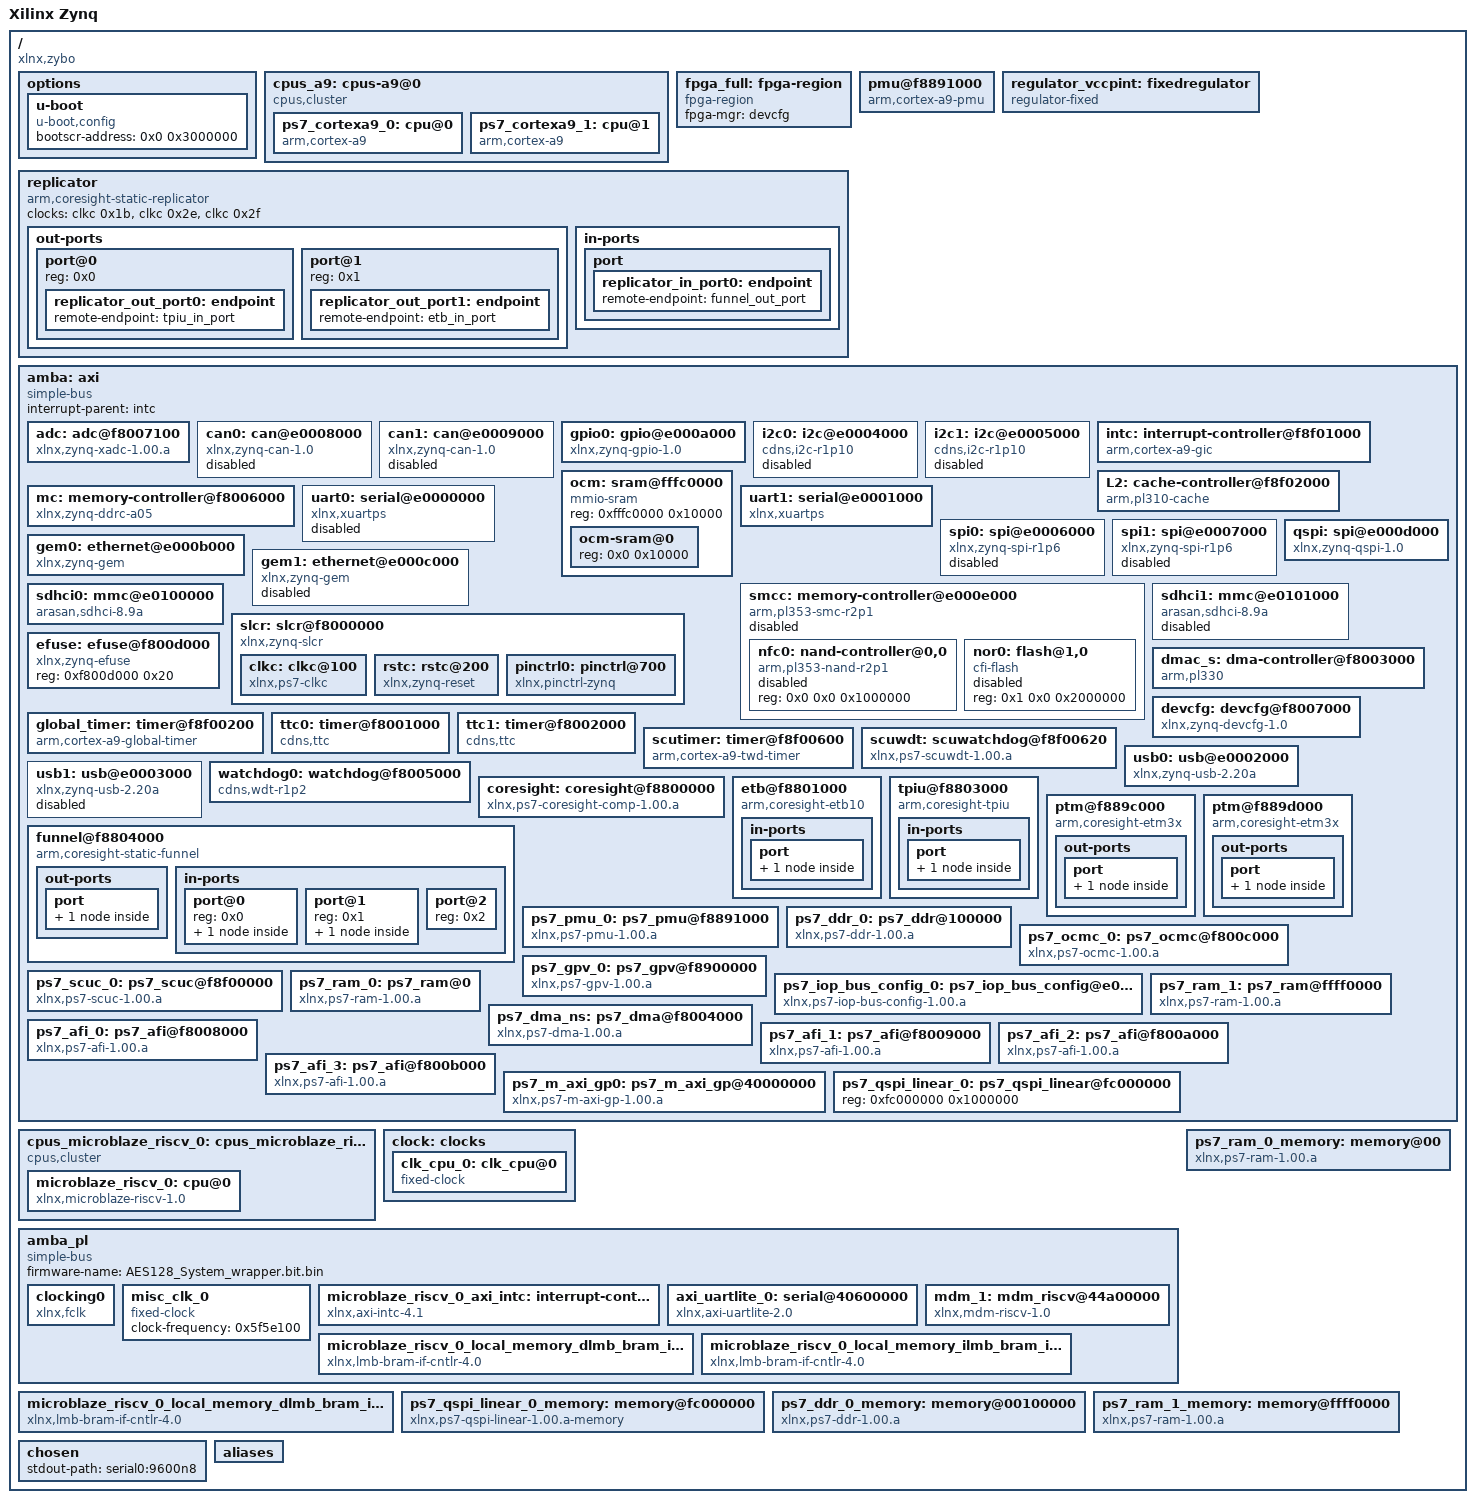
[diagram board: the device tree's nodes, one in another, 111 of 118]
/dts-v1/;
/ {
        #address-cells = <0x1>;
        #size-cells = <0x1>;
        compatible = "xlnx,zybo";
        model = "Xilinx Zynq";
        board = "zybo";
        device_id = "7z010";
        slrcount = <0x1>;
        family = "Zynq";
        speed_grade = "1";

        options {

                u-boot {
                        compatible = "u-boot,config";
                        bootscr-address = <0x0 0x3000000>;
                };
        };

        cpus_a9: cpus-a9@0 {
                phandle = <0x37>;
                #address-cells = <0x1>;
                #size-cells = <0x0>;
                compatible = "cpus,cluster";
                address-map = <0xf0000000 &amba 0xf0000000 0x10000000>,
                 <0x100000 &ps7_ddr_0_memory 0x100000 0x1ff00000>,
                 <0x0 &ps7_ram_0_memory 0x0 0x30000>,
                 <0xffff0000 &ps7_ram_1_memory 0xffff0000 0xfe00>,
                 <0x40600000 &axi_uartlite_0 0x40600000 0x10000>,
                 <0x41200000 &microblaze_riscv_0_axi_intc 0x41200000 0x10000>,
                 <0x44a00000 &mdm_1 0x44a00000 0x10000>,
                 <0xf8008000 &ps7_afi_0 0xf8008000 0x1000>,
                 <0xf8009000 &ps7_afi_1 0xf8009000 0x1000>,
                 <0xf800a000 &ps7_afi_2 0xf800a000 0x1000>,
                 <0xf800b000 &ps7_afi_3 0xf800b000 0x1000>,
                 <0xf8800000 &coresight 0xf8800000 0x100000>,
                 <0xf8006000 &mc 0xf8006000 0x1000>,
                 <0xf8007000 &devcfg 0xf8007000 0x100>,
                 <0xf8004000 &ps7_dma_ns 0xf8004000 0x1000>,
                 <0xf8003000 &dmac_s 0xf8003000 0x1000>,
                 <0xe000b000 &gem0 0xe000b000 0x1000>,
                 <0xf8f00200 &global_timer 0xf8f00200 0x100>,
                 <0xe000a000 &gpio0 0xe000a000 0x1000>,
                 <0xf8900000 &ps7_gpv_0 0xf8900000 0x100000>,
                 <0xf8f01000 &intc 0xf8f01000 0x1000>,
                 <0xe0200000 &ps7_iop_bus_config_0 0xe0200000 0x1000>,
                 <0xf8f02000 &L2 0xf8f02000 0x1000>,
                 <0xf800c000 &ps7_ocmc_0 0xf800c000 0x1000>,
                 <0xf8891000 &ps7_pmu_0 0xf8891000 0x1000>,
                 <0xe000d000 &qspi 0xe000d000 0x1000>,
                 <0xfc000000 &ps7_qspi_linear_0_memory 0xfc000000 0x1000000>,
                 <0xf8f00000 &ps7_scuc_0 0xf8f00000 0xfd>,
                 <0xf8f00600 &scutimer 0xf8f00600 0x20>,
                 <0xf8f00620 &scuwdt 0xf8f00620 0xe0>,
                 <0xe0100000 &sdhci0 0xe0100000 0x1000>,
                 <0xf8000000 &slcr 0xf8000000 0x1000>,
                 <0xf8001000 &ttc0 0xf8001000 0x1000>,
                 <0xe0001000 &uart1 0xe0001000 0x1000>,
                 <0xe0002000 &usb0 0xe0002000 0x1000>,
                 <0xf8007100 &adc 0xf8007100 0x21>;
                #ranges-address-cells = <0x1>;
                #ranges-size-cells = <0x1>;

                ps7_cortexa9_0: cpu@0 {
                        phandle = <0x2f>;
                        compatible = "arm,cortex-a9";
                        device_type = "cpu";
                        reg = <0x0>;
                        clocks = <&clkc 0x3>;
                        clock-latency = <0x3e8>;
                        cpu0-supply = <&regulator_vccpint>;
                        operating-points = <0xa2c2b 0xf4240 0x51616 0xf4240>;
                        xlnx,i-cache-size = <0x8000>;
                        xlnx,d-cache-line-size = <0x14>;
                        xlnx,i-cache-line-size = <0x14>;
                        xlnx,cpu-1x-clk-freq-hz = <0x6750918>;
                        xlnx,ip-name = "ps7_cortexa9";
                        xlnx,d-cache-size = <0x8000>;
                        xlnx,num-cores = <0x2>;
                        xlnx,cpu-clk-freq-hz = <0x26be3680>;
                        bus-handle = <0x1>;
                };

                ps7_cortexa9_1: cpu@1 {
                        phandle = <0x31>;
                        compatible = "arm,cortex-a9";
                        device_type = "cpu";
                        reg = <0x1>;
                        clocks = <&clkc 0x3>;
                        xlnx,i-cache-size = <0x8000>;
                        xlnx,d-cache-line-size = <0x14>;
                        xlnx,i-cache-line-size = <0x14>;
                        xlnx,cpu-1x-clk-freq-hz = <0x6750918>;
                        xlnx,ip-name = "ps7_cortexa9";
                        xlnx,d-cache-size = <0x8000>;
                        xlnx,cpu-clk-freq-hz = <0x26be3680>;
                        bus-handle = <0x1>;
                };
        };

        fpga_full: fpga-region {
                phandle = <0x38>;
                compatible = "fpga-region";
                fpga-mgr = <&devcfg>;
                #address-cells = <0x1>;
                #size-cells = <0x1>;
                ranges;
        };

        pmu@f8891000 {
                compatible = "arm,cortex-a9-pmu";
                interrupts = <0x0 0x5 0x4 0x0 0x6 0x4>;
                interrupt-parent = <&intc>;
                reg = <0xf8891000 0x1000 0xf8893000 0x1000>;
        };

        regulator_vccpint: fixedregulator {
                phandle = <0x26>;
                compatible = "regulator-fixed";
                regulator-name = "VCCPINT";
                regulator-min-microvolt = <0xf4240>;
                regulator-max-microvolt = <0xf4240>;
                regulator-boot-on;
                regulator-always-on;
        };

        replicator {
                compatible = "arm,coresight-static-replicator";
                clocks = <&clkc 0x1b>,
                 <&clkc 0x2e>,
                 <&clkc 0x2f>;
                clock-names = "apb_pclk", "dbg_trc", "dbg_apb";

                out-ports {
                        #address-cells = <0x1>;
                        #size-cells = <0x0>;

                        port@0 {
                                reg = <0x0>;

                                replicator_out_port0: endpoint {
                                        phandle = <0x2b>;
                                        remote-endpoint = <&tpiu_in_port>;
                                };
                        };

                        port@1 {
                                reg = <0x1>;

                                replicator_out_port1: endpoint {
                                        phandle = <0x2a>;
                                        remote-endpoint = <&etb_in_port>;
                                };
                        };
                };

                in-ports {

                        port {

                                replicator_in_port0: endpoint {
                                        phandle = <0x2c>;
                                        remote-endpoint = <&funnel_out_port>;
                                };
                        };
                };
        };

        amba: axi {
                phandle = <0x1>;
                bootph-all;
                compatible = "simple-bus";
                #address-cells = <0x1>;
                #size-cells = <0x1>;
                interrupt-parent = <&intc>;
                ranges;

                adc: adc@f8007100 {
                        phandle = <0x24>;
                        compatible = "xlnx,zynq-xadc-1.00.a";
                        reg = <0xf8007100 0x20>;
                        interrupts = <0x0 0x7 0x4>;
                        interrupt-parent = <&intc>;
                        clocks = <&clkc 0xc>;
                        status = "okay";
                        xlnx,ip-name = "ps7_xadc";
                        xlnx,name = "ps7_xadc_0";
                };

                can0: can@e0008000 {
                        phandle = <0x39>;
                        compatible = "xlnx,zynq-can-1.0";
                        status = "disabled";
                        clocks = <&clkc 0x13>,
                         <&clkc 0x24>;
                        clock-names = "can_clk", "pclk";
                        reg = <0xe0008000 0x1000>;
                        interrupts = <0x0 0x1c 0x4>;
                        interrupt-parent = <&intc>;
                        tx-fifo-depth = <0x40>;
                        rx-fifo-depth = <0x40>;
                };

                can1: can@e0009000 {
                        phandle = <0x3a>;
                        compatible = "xlnx,zynq-can-1.0";
                        status = "disabled";
                        clocks = <&clkc 0x14>,
                         <&clkc 0x25>;
                        clock-names = "can_clk", "pclk";
                        reg = <0xe0009000 0x1000>;
                        interrupts = <0x0 0x33 0x4>;
                        interrupt-parent = <&intc>;
                        tx-fifo-depth = <0x40>;
                        rx-fifo-depth = <0x40>;
                };

                gpio0: gpio@e000a000 {
                        phandle = <0x13>;
                        compatible = "xlnx,zynq-gpio-1.0";
                        #gpio-cells = <0x2>;
                        clocks = <&clkc 0x2a>;
                        gpio-controller;
                        interrupt-controller;
                        #interrupt-cells = <0x2>;
                        interrupt-parent = <&intc>;
                        interrupts = <0x0 0x14 0x4>;
                        reg = <0xe000a000 0x1000>;
                        xlnx,mio-gpio-mask = <0x5600>;
                        status = "okay";
                        gpio-mask-high = <0x0>;
                        xlnx,emio-gpio-width = <0x40>;
                        xlnx,ip-name = "ps7_gpio";
                        gpio-mask-low = <0x5600>;
                        emio-gpio-width = <0x40>;
                        xlnx,name = "ps7_gpio_0";
                };

                i2c0: i2c@e0004000 {
                        phandle = <0x3b>;
                        compatible = "cdns,i2c-r1p10";
                        status = "disabled";
                        clocks = <&clkc 0x26>;
                        interrupt-parent = <&intc>;
                        interrupts = <0x0 0x19 0x4>;
                        clock-frequency = <0x61a80>;
                        reg = <0xe0004000 0x1000>;
                        #address-cells = <0x1>;
                        #size-cells = <0x0>;
                };

                i2c1: i2c@e0005000 {
                        phandle = <0x3c>;
                        compatible = "cdns,i2c-r1p10";
                        status = "disabled";
                        clocks = <&clkc 0x27>;
                        interrupt-parent = <&intc>;
                        interrupts = <0x0 0x30 0x4>;
                        clock-frequency = <0x61a80>;
                        reg = <0xe0005000 0x1000>;
                        #address-cells = <0x1>;
                        #size-cells = <0x0>;
                };

                intc: interrupt-controller@f8f01000 {
                        phandle = <0x15>;
                        compatible = "arm,cortex-a9-gic";
                        #interrupt-cells = <0x3>;
                        interrupt-controller;
                        reg = <0xf8f01000 0x1000 0xf8f00100 0x100>;
                        status = "okay";
                        xlnx,irq-f2p-mode = "DIRECT";
                        xlnx,ip-name = "ps7_intc_dist";
                        xlnx,name = "ps7_intc_dist_0";
                };

                L2: cache-controller@f8f02000 {
                        phandle = <0x17>;
                        compatible = "arm,pl310-cache";
                        reg = <0xf8f02000 0x1000>;
                        interrupts = <0x0 0x2 0x4>;
                        arm,data-latency = <0x3 0x2 0x2>;
                        arm,tag-latency = <0x2 0x2 0x2>;
                        cache-unified;
                        cache-level = <0x2>;
                        status = "okay";
                        xlnx,ip-name = "ps7_pl310";
                        xlnx,name = "ps7_pl310_0";
                };

                mc: memory-controller@f8006000 {
                        phandle = <0xd>;
                        compatible = "xlnx,zynq-ddrc-a05";
                        reg = <0xf8006000 0x1000>;
                        status = "okay";
                        xlnx,ddr-clk-freq-hz = <0x1f4add40>;
                        xlnx,ip-name = "ps7_ddrc";
                        xlnx,has-ecc = <0x0>;
                        xlnx,name = "ps7_ddrc_0";
                };

                ocm: sram@fffc0000 {
                        phandle = <0x3d>;
                        compatible = "mmio-sram";
                        reg = <0xfffc0000 0x10000>;
                        #address-cells = <0x1>;
                        #size-cells = <0x1>;
                        ranges = <0x0 0xfffc0000 0x10000>;

                        ocm-sram@0 {
                                reg = <0x0 0x10000>;
                        };
                };

                uart0: serial@e0000000 {
                        phandle = <0x3e>;
                        compatible = "xlnx,xuartps", "cdns,uart-r1p8";
                        status = "disabled";
                        clocks = <&clkc 0x17>,
                         <&clkc 0x28>;
                        clock-names = "uart_clk", "pclk";
                        reg = <0xe0000000 0x1000>;
                        interrupts = <0x0 0x1b 0x4>;
                        interrupt-parent = <&intc>;
                };

                uart1: serial@e0001000 {
                        phandle = <0x22>;
                        compatible = "xlnx,xuartps", "cdns,uart-r1p8";
                        status = "okay";
                        clocks = <&clkc 0x18>,
                         <&clkc 0x29>;
                        clock-names = "uart_clk", "pclk";
                        reg = <0xe0001000 0x1000>;
                        interrupts = <0x0 0x32 0x4>;
                        interrupt-parent = <&intc>;
                        xlnx,clock-freq = <0x5f5e100>;
                        xlnx,has-modem = <0x0>;
                        xlnx,ip-name = "ps7_uart";
                        cts-override;
                        port-number = <0x0>;
                        xlnx,uart-clk-freq-hz = <0x5f5e100>;
                        xlnx,name = "ps7_uart_1";
                };

                spi0: spi@e0006000 {
                        phandle = <0x3f>;
                        compatible = "xlnx,zynq-spi-r1p6";
                        reg = <0xe0006000 0x1000>;
                        status = "disabled";
                        interrupt-parent = <&intc>;
                        interrupts = <0x0 0x1a 0x4>;
                        clocks = <&clkc 0x19>,
                         <&clkc 0x22>;
                        clock-names = "ref_clk", "pclk";
                        #address-cells = <0x1>;
                        #size-cells = <0x0>;
                };

                spi1: spi@e0007000 {
                        phandle = <0x40>;
                        compatible = "xlnx,zynq-spi-r1p6";
                        reg = <0xe0007000 0x1000>;
                        status = "disabled";
                        interrupt-parent = <&intc>;
                        interrupts = <0x0 0x31 0x4>;
                        clocks = <&clkc 0x1a>,
                         <&clkc 0x23>;
                        clock-names = "ref_clk", "pclk";
                        #address-cells = <0x1>;
                        #size-cells = <0x0>;
                };

                qspi: spi@e000d000 {
                        phandle = <0x1a>;
                        compatible = "xlnx,zynq-qspi-1.0";
                        reg = <0xe000d000 0x1000>;
                        interrupt-parent = <&intc>;
                        interrupts = <0x0 0x13 0x4>;
                        clocks = <&clkc 0xa>,
                         <&clkc 0x2b>;
                        clock-names = "ref_clk", "pclk";
                        status = "okay";
                        #address-cells = <0x1>;
                        #size-cells = <0x0>;
                        xlnx,qspi-fbclk = <0x0>;
                        num-cs = <0x1>;
                        xlnx,qspi-clk-freq-hz = <0xbebc200>;
                        xlnx,bus-width = <0x2>;
                        xlnx,ip-name = "ps7_qspi";
                        spi-rx-bus-width = <0x4>;
                        xlnx,connection-mode = <0x0>;
                        spi-tx-bus-width = <0x4>;
                        xlnx,clock-freq = <0xbebc200>;
                        xlnx,fb-clk = <0x1>;
                        xlnx,qspi-mode = <0x0>;
                        xlnx,name = "ps7_qspi_0";
                        xlnx,qspi-bus-width = <0x2>;
                        is-dual = <0x0>;
                };

                gem0: ethernet@e000b000 {
                        phandle = <0x11>;
                        compatible = "xlnx,zynq-gem", "cdns,gem";
                        reg = <0xe000b000 0x1000>;
                        status = "okay";
                        interrupts = <0x0 0x16 0x4>;
                        interrupt-parent = <&intc>;
                        clocks = <&clkc 0x1e>,
                         <&clkc 0x1e>,
                         <&clkc 0xd>;
                        clock-names = "pclk", "hclk", "tx_clk";
                        #address-cells = <0x1>;
                        #size-cells = <0x0>;
                        xlnx,has-mdio = <0x1>;
                        phy-mode = "rgmii-id";
                        xlnx,enet-slcr-1000mbps-div0 = <0x8>;
                        xlnx,enet-slcr-10mbps-div0 = <0x8>;
                        xlnx,enet-slcr-1000mbps-div1 = <0x1>;
                        xlnx,enet-slcr-10mbps-div1 = <0x32>;
                        xlnx,ip-name = "ps7_ethernet";
                        xlnx,eth-mode = <0x1>;
                        xlnx,enet-clk-freq-hz = <0x7735940>;
                        xlnx,enet-slcr-100mbps-div0 = <0x8>;
                        xlnx,enet-slcr-100mbps-div1 = <0x5>;
                        xlnx,name = "ps7_ethernet_0";
                };

                gem1: ethernet@e000c000 {
                        phandle = <0x41>;
                        compatible = "xlnx,zynq-gem", "cdns,gem";
                        reg = <0xe000c000 0x1000>;
                        status = "disabled";
                        interrupts = <0x0 0x2d 0x4>;
                        interrupt-parent = <&intc>;
                        clocks = <&clkc 0x1f>,
                         <&clkc 0x1f>,
                         <&clkc 0xe>;
                        clock-names = "pclk", "hclk", "tx_clk";
                        #address-cells = <0x1>;
                        #size-cells = <0x0>;
                };

                smcc: memory-controller@e000e000 {
                        phandle = <0x42>;
                        compatible = "arm,pl353-smc-r2p1", "arm,primecell";
                        reg = <0xe000e000 0x1000>;
                        status = "disabled";
                        clock-names = "memclk", "apb_pclk";
                        clocks = <&clkc 0xb>,
                         <&clkc 0x2c>;
                        ranges = <0x0 0x0 0xe1000000 0x1000000 0x1 0x0 0xe2000000 0x2000000 0x2 0x0 0xe4000000 0x2000000>;
                        #address-cells = <0x2>;
                        #size-cells = <0x1>;
                        interrupt-parent = <&intc>;
                        interrupts = <0x0 0x12 0x4>;

                        nfc0: nand-controller@0,0 {
                                phandle = <0x43>;
                                compatible = "arm,pl353-nand-r2p1";
                                reg = <0x0 0x0 0x1000000>;
                                status = "disabled";
                        };

                        nor0: flash@1,0 {
                                phandle = <0x44>;
                                status = "disabled";
                                compatible = "cfi-flash";
                                reg = <0x1 0x0 0x2000000>;
                        };
                };

                sdhci0: mmc@e0100000 {
                        phandle = <0x1f>;
                        compatible = "arasan,sdhci-8.9a";
                        status = "okay";
                        clock-names = "clk_xin", "clk_ahb";
                        clocks = <&clkc 0x15>,
                         <&clkc 0x20>;
                        interrupt-parent = <&intc>;
                        interrupts = <0x0 0x18 0x4>;
                        reg = <0xe0100000 0x1000>;
                        xlnx,has-power = <0x0>;
                        xlnx,ip-name = "ps7_sdio";
                        xlnx,sdio-clk-freq-hz = <0x2faf080>;
                        xlnx,has-wp = <0x1>;
                        xlnx,has-cd = <0x1>;
                        xlnx,name = "ps7_sd_0";
                };

                sdhci1: mmc@e0101000 {
                        phandle = <0x45>;
                        compatible = "arasan,sdhci-8.9a";
                        status = "disabled";
                        clock-names = "clk_xin", "clk_ahb";
                        clocks = <&clkc 0x16>,
                         <&clkc 0x21>;
                        interrupt-parent = <&intc>;
                        interrupts = <0x0 0x2f 0x4>;
                        reg = <0xe0101000 0x1000>;
                };

                slcr: slcr@f8000000 {
                        phandle = <0x20>;
                        bootph-all;
                        #address-cells = <0x1>;
                        #size-cells = <0x1>;
                        compatible = "xlnx,zynq-slcr", "syscon", "simple-mfd";
                        reg = <0xf8000000 0x1000>;
                        ranges;
                        status = "okay";
                        xlnx,ip-name = "ps7_slcr";
                        xlnx,name = "ps7_slcr_0";

                        clkc: clkc@100 {
                                phandle = <0x25>;
                                bootph-all;
                                #clock-cells = <0x1>;
                                compatible = "xlnx,ps7-clkc";
                                fclk-enable = <0x1>;
                                clock-output-names = "armpll", "ddrpll", "iopll", "cpu_6or4x", "cpu_3or2x", "cpu_2x", "cpu_1x", "ddr2x", "ddr3x", "dci", "lqspi", "smc", "pcap", "gem0", "gem1", "fclk0", "fclk1", "fclk2", "fclk3", "can0", "can1", "sdio0", "sdio1", "uart0", "uart1", "spi0", "spi1", "dma", "usb0_aper", "usb1_aper", "gem0_aper", "gem1_aper", "sdio0_aper", "sdio1_aper", "spi0_aper", "spi1_aper", "can0_aper", "can1_aper", "i2c0_aper", "i2c1_aper", "uart0_aper", "uart1_aper", "gpio_aper", "lqspi_aper", "smc_aper", "swdt", "dbg_trc", "dbg_apb";
                                reg = <0x100 0x100>;
                                ps-clk-frequency = <0x2faf080>;
                        };

                        rstc: rstc@200 {
                                phandle = <0x46>;
                                compatible = "xlnx,zynq-reset";
                                reg = <0x200 0x48>;
                                #reset-cells = <0x1>;
                                syscon = <&slcr>;
                        };

                        pinctrl0: pinctrl@700 {
                                phandle = <0x47>;
                                compatible = "xlnx,pinctrl-zynq";
                                reg = <0x700 0x200>;
                                syscon = <&slcr>;
                        };
                };

                dmac_s: dma-controller@f8003000 {
                        phandle = <0x10>;
                        compatible = "arm,pl330", "arm,primecell";
                        reg = <0xf8003000 0x1000>;
                        interrupt-parent = <&intc>;
                        interrupts = <0x0 0xd 0x4 0x0 0xe 0x4 0x0 0xf 0x4 0x0 0x10 0x4 0x0 0x11 0x4 0x0 0x28 0x4 0x0 0x29 0x4 0x0 0x2a 0x4 0x0 0x2b 0x4>;
                        #dma-cells = <0x1>;
                        clocks = <&clkc 0x1b>;
                        clock-names = "apb_pclk";
                        status = "okay";
                        xlnx,ip-name = "ps7_dma";
                        xlnx,is-secure;
                        xlnx,name = "ps7_dma_s";
                };

                devcfg: devcfg@f8007000 {
                        phandle = <0xe>;
                        compatible = "xlnx,zynq-devcfg-1.0";
                        reg = <0xf8007000 0x100>;
                        interrupt-parent = <&intc>;
                        interrupts = <0x0 0x8 0x4>;
                        clocks = <&clkc 0xc>,
                         <&clkc 0xf>,
                         <&clkc 0x10>,
                         <&clkc 0x11>,
                         <&clkc 0x12>;
                        clock-names = "ref_clk", "fclk0", "fclk1", "fclk2", "fclk3";
                        syscon = <&slcr>;
                        status = "okay";
                        xlnx,ip-name = "ps7_dev_cfg";
                        xlnx,name = "ps7_dev_cfg_0";
                };

                efuse: efuse@f800d000 {
                        phandle = <0x48>;
                        compatible = "xlnx,zynq-efuse";
                        reg = <0xf800d000 0x20>;
                };

                global_timer: timer@f8f00200 {
                        phandle = <0x12>;
                        compatible = "arm,cortex-a9-global-timer";
                        reg = <0xf8f00200 0x20>;
                        interrupts = <0x1 0xb 0x301>;
                        interrupt-parent = <&intc>;
                        clocks = <&clkc 0x4>;
                        status = "okay";
                        xlnx,ip-name = "ps7_globaltimer";
                        xlnx,name = "ps7_globaltimer_0";
                };

                ttc0: timer@f8001000 {
                        phandle = <0x21>;
                        interrupt-parent = <&intc>;
                        interrupts = <0x0 0xa 0x4 0x0 0xb 0x4 0x0 0xc 0x4>;
                        compatible = "cdns,ttc";
                        clocks = <&clkc 0x6>;
                        reg = <0xf8001000 0x1000>;
                        xlnx,ttc-clk2-freq-hz = <0x6750918>;
                        xlnx,ttc-clk1-clksrc = <0x0>;
                        status = "okay";
                        xlnx,clock-freq = <0x6750918>;
                        xlnx,ttc-clk2-clksrc = <0x0>;
                        xlnx,ip-name = "ps7_ttc";
                        xlnx,ttc-clk0-freq-hz = <0x6750918>;
                        xlnx,ttc-clk1-freq-hz = <0x6750918>;
                        xlnx,ttc-clk0-clksrc = <0x0>;
                        xlnx,name = "ps7_ttc_0";
                };

                ttc1: timer@f8002000 {
                        phandle = <0x49>;
                        interrupt-parent = <&intc>;
                        interrupts = <0x0 0x25 0x4 0x0 0x26 0x4 0x0 0x27 0x4>;
                        compatible = "cdns,ttc";
                        clocks = <&clkc 0x6>;
                        reg = <0xf8002000 0x1000>;
                };

                scutimer: timer@f8f00600 {
                        phandle = <0x1d>;
                        bootph-all;
                        interrupt-parent = <&intc>;
                        interrupts = <0x1 0xd 0x301>;
                        compatible = "arm,cortex-a9-twd-timer";
                        reg = <0xf8f00600 0x20>;
                        clocks = <&clkc 0x4>;
                        status = "okay";
                        xlnx,ip-name = "ps7_scutimer";
                        xlnx,name = "ps7_scutimer_0";
                };

                scuwdt: scuwatchdog@f8f00620 {
                        phandle = <0x1e>;
                        interrupt-parent = <&intc>;
                        interrupts = <0x1 0xe 0x4>;
                        compatible = "xlnx,ps7-scuwdt-1.00.a";
                        reg = <0xf8f00620 0xe0>;
                        status = "okay";
                        xlnx,ip-name = "ps7_scuwdt";
                        xlnx,name = "ps7_scuwdt_0";
                };

                usb0: usb@e0002000 {
                        phandle = <0x23>;
                        compatible = "xlnx,zynq-usb-2.20a", "chipidea,usb2";
                        status = "okay";
                        clocks = <&clkc 0x1c>;
                        interrupt-parent = <&intc>;
                        interrupts = <0x0 0x15 0x4>;
                        reg = <0xe0002000 0x1000>;
                        phy_type = "ulpi";
                        xlnx,usb-reset = "MIO , 46";
                        xlnx,ip-name = "ps7_usb";
                        xlnx,enable-superspeed = <0x0>;
                        usb-reset = <0x13 0x2e 0x0>;
                        xlnx,name = "ps7_usb_0";
                };

                usb1: usb@e0003000 {
                        phandle = <0x4a>;
                        compatible = "xlnx,zynq-usb-2.20a", "chipidea,usb2";
                        status = "disabled";
                        clocks = <&clkc 0x1d>;
                        interrupt-parent = <&intc>;
                        interrupts = <0x0 0x2c 0x4>;
                        reg = <0xe0003000 0x1000>;
                        phy_type = "ulpi";
                };

                watchdog0: watchdog@f8005000 {
                        phandle = <0x4b>;
                        clocks = <&clkc 0x2d>;
                        compatible = "cdns,wdt-r1p2";
                        interrupt-parent = <&intc>;
                        interrupts = <0x0 0x9 0x1>;
                        reg = <0xf8005000 0x1000>;
                        timeout-sec = <0xa>;
                };

                coresight: coresight@f8800000 {
                        phandle = <0xc>;
                        compatible = "xlnx,ps7-coresight-comp-1.00.a";
                        status = "okay";
                        reg = <0xf8800000 0x100000>;
                        xlnx,ip-name = "ps7_coresight_comp";
                        xlnx,name = "ps7_coresight_comp_0";
                };

                etb@f8801000 {
                        compatible = "arm,coresight-etb10", "arm,primecell";
                        reg = <0xf8801000 0x1000>;
                        clocks = <&clkc 0x1b>,
                         <&clkc 0x2e>,
                         <&clkc 0x2f>;
                        clock-names = "apb_pclk", "dbg_trc", "dbg_apb";

                        in-ports {

                                port {

                                        etb_in_port: endpoint {
                                                phandle = <0x28>;
                                                remote-endpoint = <&replicator_out_port1>;
                                        };
                                };
                        };
                };

                tpiu@f8803000 {
                        compatible = "arm,coresight-tpiu", "arm,primecell";
                        reg = <0xf8803000 0x1000>;
                        clocks = <&clkc 0x1b>,
                         <&clkc 0x2e>,
                         <&clkc 0x2f>;
                        clock-names = "apb_pclk", "dbg_trc", "dbg_apb";

                        in-ports {

                                port {

                                        tpiu_in_port: endpoint {
                                                phandle = <0x27>;
                                                remote-endpoint = <&replicator_out_port0>;
                                        };
                                };
                        };
                };

                funnel@f8804000 {
                        compatible = "arm,coresight-static-funnel", "arm,primecell";
                        reg = <0xf8804000 0x1000>;
                        clocks = <&clkc 0x1b>,
                         <&clkc 0x2e>,
                         <&clkc 0x2f>;
                        clock-names = "apb_pclk", "dbg_trc", "dbg_apb";

                        out-ports {

                                port {

                                        funnel_out_port: endpoint {
                                                phandle = <0x29>;
                                                remote-endpoint = <&replicator_in_port0>;
                                        };
                                };
                        };

                        in-ports {
                                #address-cells = <0x1>;
                                #size-cells = <0x0>;

                                port@0 {
                                        reg = <0x0>;

                                        funnel0_in_port0: endpoint {
                                                phandle = <0x30>;
                                                remote-endpoint = <&ptm0_out_port>;
                                        };
                                };

                                port@1 {
                                        reg = <0x1>;

                                        funnel0_in_port1: endpoint {
                                                phandle = <0x32>;
                                                remote-endpoint = <&ptm1_out_port>;
                                        };
                                };

                                port@2 {
                                        reg = <0x2>;
                                };
                        };
                };

                ptm@f889c000 {
                        compatible = "arm,coresight-etm3x", "arm,primecell";
                        reg = <0xf889c000 0x1000>;
                        clocks = <&clkc 0x1b>,
                         <&clkc 0x2e>,
                         <&clkc 0x2f>;
                        clock-names = "apb_pclk", "dbg_trc", "dbg_apb";
                        cpu = <&ps7_cortexa9_0>;

                        out-ports {

                                port {

                                        ptm0_out_port: endpoint {
                                                phandle = <0x2d>;
                                                remote-endpoint = <&funnel0_in_port0>;
                                        };
                                };
                        };
                };

                ptm@f889d000 {
                        compatible = "arm,coresight-etm3x", "arm,primecell";
                        reg = <0xf889d000 0x1000>;
                        clocks = <&clkc 0x1b>,
                         <&clkc 0x2e>,
                         <&clkc 0x2f>;
                        clock-names = "apb_pclk", "dbg_trc", "dbg_apb";
                        cpu = <&ps7_cortexa9_1>;

                        out-ports {

                                port {

                                        ptm1_out_port: endpoint {
                                                phandle = <0x2e>;
                                                remote-endpoint = <&funnel0_in_port1>;
                                        };
                                };
                        };
                };

                ps7_pmu_0: ps7_pmu@f8891000 {
                        phandle = <0x19>;
                        compatible = "xlnx,ps7-pmu-1.00.a";
                        status = "okay";
                        xlnx,ip-name = "ps7_pmu";
                        reg = <0xf8891000 0x1000 0xf8893000 0x1000>;
                        xlnx,name = "ps7_pmu_0";
                };

                ps7_ddr_0: ps7_ddr@100000 {
                        phandle = <0x4c>;
                        compatible = "xlnx,ps7-ddr-1.00.a";
                        status = "okay";
                        xlnx,ip-name = "ps7_ddr";
                        reg = <0x100000 0x1ff00000>;
                        xlnx,name = "ps7_ddr_0";
                };

                ps7_ocmc_0: ps7_ocmc@f800c000 {
                        phandle = <0x18>;
                        compatible = "xlnx,ps7-ocmc-1.00.a";
                        status = "okay";
                        xlnx,ip-name = "ps7_ocmc";
                        reg = <0xf800c000 0x1000>;
                        xlnx,name = "ps7_ocmc_0";
                };

                ps7_gpv_0: ps7_gpv@f8900000 {
                        phandle = <0x14>;
                        compatible = "xlnx,ps7-gpv-1.00.a";
                        status = "okay";
                        xlnx,ip-name = "ps7_gpv";
                        reg = <0xf8900000 0x100000>;
                        xlnx,name = "ps7_gpv_0";
                };

                ps7_scuc_0: ps7_scuc@f8f00000 {
                        phandle = <0x1c>;
                        compatible = "xlnx,ps7-scuc-1.00.a";
                        status = "okay";
                        xlnx,ip-name = "ps7_scuc";
                        reg = <0xf8f00000 0xfd>;
                        xlnx,name = "ps7_scuc_0";
                };

                ps7_iop_bus_config_0: ps7_iop_bus_config@e0200000 {
                        phandle = <0x16>;
                        compatible = "xlnx,ps7-iop-bus-config-1.00.a";
                        status = "okay";
                        xlnx,ip-name = "ps7_iop_bus_config";
                        reg = <0xe0200000 0x1000>;
                        xlnx,name = "ps7_iop_bus_config_0";
                };

                ps7_ram_0: ps7_ram@0 {
                        phandle = <0x4d>;
                        compatible = "xlnx,ps7-ram-1.00.a";
                        status = "okay";
                        xlnx,ip-name = "ps7_ram";
                        reg = <0x0 0x30000>;
                        xlnx,name = "ps7_ram_0";
                };

                ps7_ram_1: ps7_ram@ffff0000 {
                        phandle = <0x4e>;
                        compatible = "xlnx,ps7-ram-1.00.a";
                        status = "okay";
                        xlnx,ip-name = "ps7_ram";
                        reg = <0xffff0000 0xfe00>;
                        xlnx,name = "ps7_ram_1";
                };

                ps7_dma_ns: ps7_dma@f8004000 {
                        phandle = <0xf>;
                        compatible = "xlnx,ps7-dma-1.00.a";
                        status = "okay";
                        xlnx,ip-name = "ps7_dma";
                        xlnx,is-secure;
                        reg = <0xf8004000 0x1000>;
                        xlnx,name = "ps7_dma_ns";
                };

                ps7_afi_0: ps7_afi@f8008000 {
                        phandle = <0x8>;
                        compatible = "xlnx,ps7-afi-1.00.a";
                        status = "okay";
                        xlnx,ip-name = "ps7_afi";
                        reg = <0xf8008000 0x1000>;
                        xlnx,name = "ps7_afi_0";
                };

                ps7_afi_1: ps7_afi@f8009000 {
                        phandle = <0x9>;
                        compatible = "xlnx,ps7-afi-1.00.a";
                        status = "okay";
                        xlnx,ip-name = "ps7_afi";
                        reg = <0xf8009000 0x1000>;
                        xlnx,name = "ps7_afi_1";
                };

                ps7_afi_2: ps7_afi@f800a000 {
                        phandle = <0xa>;
                        compatible = "xlnx,ps7-afi-1.00.a";
                        status = "okay";
                        xlnx,ip-name = "ps7_afi";
                        reg = <0xf800a000 0x1000>;
                        xlnx,name = "ps7_afi_2";
                };

                ps7_afi_3: ps7_afi@f800b000 {
                        phandle = <0xb>;
                        compatible = "xlnx,ps7-afi-1.00.a";
                        status = "okay";
                        xlnx,ip-name = "ps7_afi";
                        reg = <0xf800b000 0x1000>;
                        xlnx,name = "ps7_afi_3";
                };

                ps7_m_axi_gp0: ps7_m_axi_gp@40000000 {
                        phandle = <0x4f>;
                        compatible = "xlnx,ps7-m-axi-gp-1.00.a";
                        status = "okay";
                        xlnx,ip-name = "ps7_m_axi_gp";
                        xlnx,is-hierarchy;
                        reg = <0x40000000 0x40000000>;
                        xlnx,name = "ps7_m_axi_gp0";
                };

                ps7_qspi_linear_0: ps7_qspi_linear@fc000000 {
                        phandle = <0x50>;
                        reg = <0xfc000000 0x1000000>;
                };
        };

        cpus_microblaze_riscv_0: cpus_microblaze_riscv@0 {
                phandle = <0x51>;
                #cpu-mask-cells = <0x1>;
                compatible = "cpus,cluster";
                #address-cells = <0x1>;
                #size-cells = <0x0>;
                address-map = <0x0 &microblaze_riscv_0_local_memory_dlmb_bram_if_cntlr_memory 0x0 0x8000>,
                 <0x0 &microblaze_riscv_0_local_memory_dlmb_bram_if_cntlr 0x0 0x8000>,
                 <0x40600000 &axi_uartlite_0 0x40600000 0x10000>,
                 <0x41200000 &microblaze_riscv_0_axi_intc 0x41200000 0x10000>,
                 <0x44a00000 &mdm_1 0x44a00000 0x10000>;
                #ranges-address-cells = <0x1>;
                #ranges-size-cells = <0x1>;

                microblaze_riscv_0: cpu@0 {
                        phandle = <0x52>;
                        xlnx,d-axi = <0x1>;
                        xlnx,pmp-entries = <0x0>;
                        xlnx,temporal-depth = <0x0>;
                        xlnx,dcache-force-tag-lutram = <0x0>;
                        reg = <0x0>;
                        xlnx,interrupt-is-edge = <0x0>;
                        xlnx,use-mmu = <0x0>;
                        xlnx,dc-axi-mon = <0x0>;
                        xlnx,debug-trace-async-reset = <0x0>;
                        xlnx,part = "xc7z010clg400-1";
                        xlnx,use-config-reset = <0x0>;
                        xlnx,family = "zynq";
                        xlnx,use-sleep = <0x0>;
                        xlnx,d-lmb = <0x1>;
                        xlnx,enable-discrete-ports = <0x0>;
                        xlnx,debug-interface = <0x0>;
                        xlnx,use-ext-brk = <0x0>;
                        xlnx,debug-enabled = <0x1>;
                        xlnx,daddr-size = <0x20>;
                        xlnx,use-extended-fsl-instr = <0x0>;
                        xlnx,branch-target-cache-size = <0x0>;
                        bus-handle = <0x35>;
                        xlnx,pmp-addr0 = <0x0>;
                        xlnx,pmp-addr1 = <0x0>;
                        xlnx,pmp-addr2 = <0x0>;
                        xlnx,pmp-addr3 = <0x0>;
                        xlnx,pmp-addr4 = <0x0>;
                        xlnx,edk-special = "microblaze_riscv";
                        xlnx,use-dcache = <0x0>;
                        xlnx,pmp-addr5 = <0x0>;
                        xlnx,use-muldiv = <0x0>;
                        xlnx,pmp-addr6 = <0x0>;
                        xlnx,use-axi-dp-ext-addr = <0x0>;
                        xlnx,pmp-addr7 = <0x0>;
                        xlnx,pmp-addr8 = <0x0>;
                        xlnx,pmp-addr9 = <0x0>;
                        xlnx,i-axi = <0x0>;
                        xlnx,icache-streams = <0x0>;
                        xlnx,i-lmb-has-prot = <0x0>;
                        xlnx,num-sync-ff-dbg-clk = <0x1>;
                        xlnx,icache-byte-size = <0x2000>;
                        xlnx,pmp-addr10 = <0x0>;
                        d-cache-size = <0x2000>;
                        xlnx,pmp-addr11 = <0x0>;
                        xlnx,pmp-addr12 = <0x0>;
                        xlnx,pmp-addr13 = <0x0>;
                        xlnx,pmp-addr14 = <0x0>;
                        xlnx,pmp-addr15 = <0x0>;
                        xlnx,avoid-primitives = <0x0>;
                        xlnx,pmp-addr16 = <0x0>;
                        xlnx,pmp-addr17 = <0x0>;
                        xlnx,pmp-addr18 = <0x0>;
                        xlnx,pdaddr-size = <0x20>;
                        xlnx,pmp-addr19 = <0x0>;
                        xlnx,pmp-addr20 = <0x0>;
                        xlnx,pmp-addr21 = <0x0>;
                        xlnx,i-lmb = <0x1>;
                        xlnx,pmp-addr22 = <0x0>;
                        xlnx,lmb-data-size = <0x20>;
                        xlnx,lockstep-select = <0x0>;
                        xlnx,pmp-addr23 = <0x0>;
                        timebase-frequency = <0x5f5e100>;
                        xlnx,pmp-addr24 = <0x0>;
                        xlnx,dcache-data-width = <0x0>;
                        xlnx,icache-force-tag-lutram = <0x0>;
                        xlnx,pmp-addr25 = <0x0>;
                        xlnx,pmp-addr26 = <0x0>;
                        xlnx,use-branch-target-cache = <0x0>;
                        xlnx,pmp-addr27 = <0x0>;
                        xlnx,number-of-pc-brk = <0x1>;
                        xlnx,pmp-addr28 = <0x0>;
                        xlnx,imprecise-exceptions = <0x0>;
                        xlnx,pmp-addr29 = <0x0>;
                        xlnx,pmp-addr30 = <0x0>;
                        xlnx,pmp-addr31 = <0x0>;
                        xlnx,pmp-addr32 = <0x0>;
                        model = "microblaze_riscv,1.0";
                        xlnx,pmp-addr33 = <0x0>;
                        xlnx,pmp-addr34 = <0x0>;
                        xlnx,pmp-addr35 = <0x0>;
                        xlnx,pmp-addr36 = <0x0>;
                        d-cache-highaddr = <0x3fffffff>;
                        xlnx,optimization = <0x0>;
                        xlnx,pmp-addr37 = <0x0>;
                        xlnx,pmp-addr38 = <0x0>;
                        xlnx,pmp-addr39 = <0x0>;
                        xlnx,pmp-addr40 = <0x0>;
                        xlnx,pmp-addr41 = <0x0>;
                        xlnx,d-lmb-mon = <0x0>;
                        xlnx,pmp-addr42 = <0x0>;
                        xlnx,pmp-addr43 = <0x0>;
                        xlnx,pmp-addr44 = <0x0>;
                        xlnx,pmp-addr45 = <0x0>;
                        xlnx,pmp-addr46 = <0x0>;
                        xlnx,pmp-addr47 = <0x0>;
                        xlnx,pmp-addr48 = <0x0>;
                        xlnx,fault-tolerant = <0x0>;
                        xlnx,pmp-addr49 = <0x0>;
                        xlnx,pmp-addr50 = <0x0>;
                        xlnx,pmp-addr51 = <0x0>;
                        xlnx,pmp-enhancements = <0x0>;
                        d-cache-line-size = <0x10>;
                        xlnx,mmu-privileged-instr = <0x0>;
                        xlnx,pmp-addr52 = <0x0>;
                        clock-frequency = <0x5f5e100>;
                        xlnx,pmp-addr53 = <0x0>;
                        xlnx,pmp-addr54 = <0x0>;
                        xlnx,pmp-addr55 = <0x0>;
                        xlnx,i-lmb-protocol = <0x0>;
                        xlnx,pmp-addr56 = <0x0>;
                        xlnx,pmp-addr57 = <0x0>;
                        xlnx,dp-axi-mon = <0x0>;
                        xlnx,pmp-addr58 = <0x0>;
                        xlnx,pmp-addr59 = <0x0>;
                        xlnx,pmp-addr60 = <0x0>;
                        xlnx,pmp-addr61 = <0x0>;
                        xlnx,pmp-addr62 = <0x0>;
                        xlnx,pmp-addr63 = <0x0>;
                        xlnx,debug-external-trace = <0x0>;
                        xlnx,addr-size = <0x20>;
                        xlnx,debug-num-progbuf = <0x2>;
                        xlnx,debug-event-counters = <0x0>;
                        xlnx,edk-iptype = "PROCESSOR";
                        xlnx,debug-latency-counters = <0x0>;
                        xlnx,interconnect = <0x2>;
                        xlnx,edge-is-positive = <0x1>;
                        xlnx,use-icache = <0x0>;
                        xlnx,async-wakeup = <0x3>;
                        xlnx,s-axi = <0x0>;
                        xlnx,use-ext-nm-brk = <0x0>;
                        xlnx,ic-axi-mon = <0x0>;
                        xlnx,archid = <0x1>;
                        xlnx,num-sync-ff-clk-irq = <0x1>;
                        xlnx,freq = <0x5f5e100>;
                        xlnx,lockstep-master = <0x0>;
                        xlnx,pmp-cfg0 = <0x0>;
                        xlnx,pmp-cfg1 = <0x0>;
                        xlnx,iaddr-size = <0x20>;
                        xlnx,interrupt-mon = <0x0>;
                        xlnx,pmp-cfg2 = <0x0>;
                        xlnx,number-of-wr-addr-brk = <0x0>;
                        xlnx,pmp-cfg3 = <0x0>;
                        xlnx,pmp-cfg4 = <0x0>;
                        xlnx,use-interrupt = <0x2>;
                        xlnx,pmp-cfg5 = <0x0>;
                        xlnx,async-interrupt = <0x1>;
                        xlnx,pc-width = <0xf>;
                        xlnx,pmp-cfg6 = <0x0>;
                        xlnx,icache-victims = <0x0>;
                        xlnx,pmp-cfg7 = <0x0>;
                        xlnx,pmp-cfg8 = <0x0>;
                        xlnx,pmp-cfg9 = <0x0>;
                        xlnx,use-bitman-a = <0x0>;
                        xlnx,use-bitman-b = <0x0>;
                        xlnx,use-bitman-c = <0x0>;
                        xlnx,i-lmb-mon = <0x0>;
                        xlnx,dcache-byte-size = <0x2000>;
                        xlnx,data-size = <0x20>;
                        compatible = "xlnx,microblaze-riscv-1.0", "xlnx,microblaze_riscv";
                        xlnx,pmp-debug-inhibit = <0x0>;
                        xlnx,use-sstc = <0x1>;
                        xlnx,fsl-exception = <0x0>;
                        xlnx,dcache-use-writeback = <0x0>;
                        device_type = "cpu";
                        xlnx,impid = <0x1>;
                        xlnx,use-bitman-s = <0x0>;
                        xlnx,base-vectors = <0x0>;
                        xlnx,icache-line-len = <0x4>;
                        xlnx,d-lmb-has-prot = <0x0>;
                        xlnx,use-barrel = <0x1>;
                        xlnx,misaligned-exceptions = <0x1>;
                        xlnx,piaddr-size = <0x20>;
                        xlnx,use-bitman = <0x0>;
                        xlnx,dcache-line-len = <0x4>;
                        xlnx,num-sync-ff-clk = <0x2>;
                        xlnx,memory-ip-list = "microblaze_riscv_0_local_memory_ilmb_bram_if_cntlr_memory", "microblaze_riscv_0_local_memory_dlmb_bram_if_cntlr_memory";
                        xlnx,number-of-rd-addr-brk = <0x0>;
                        xlnx,use-counters = <0x1>;
                        xlnx,lockstep-slave = <0x0>;
                        interrupt-handle = <0x6>;
                        xlnx,pmp-cfg10 = <0x0>;
                        xlnx,pmp-cfg11 = <0x0>;
                        xlnx,debug-profile-size = <0x0>;
                        xlnx,pmp-cfg12 = <0x0>;
                        xlnx,pmp-cfg13 = <0x0>;
                        xlnx,pmp-cfg14 = <0x0>;
                        xlnx,pmp-cfg15 = <0x0>;
                        xlnx,debug-counter-width = <0x40>;
                        xlnx,icache-data-width = <0x0>;
                        xlnx,ip-name = "microblaze_riscv";
                        xlnx,ip-axi-mon = <0x0>;
                        xlnx,d-lmb-protocol = <0x0>;
                        xlnx,trace = <0x0>;
                        xlnx,ill-instr-exception = <0x2>;
                        xlnx,debug-trace-size = <0x0>;
                        xlnx,pmp-granularity = <0x2>;
                        xlnx,num-sync-ff-dbg-trace-clk = <0x2>;
                        xlnx,ecc-use-ce-exception = <0x0>;
                        xlnx,num-sync-ff-clk-debug = <0x2>;
                        xlnx,use-atomic = <0x0>;
                        xlnx,g-template-list = <0x0>;
                        xlnx,trap-enhancement = <0x0>;
                        xlnx,hartid = <0x0>;
                        xlnx,use-fpu = <0x0>;
                        xlnx,use-non-secure = <0x0>;
                        d-cache-baseaddr = <0x0>;
                        xlnx,use-compression = <0x0>;
                        xlnx,instr-size = <0x20>;
                        xlnx,fsl-links = <0x0>;
                        xlnx,dcache-victims = <0x0>;
                        xlnx,pmp-read-only = <0x0>;
                };
        };

        clock: clocks {
                phandle = <0x53>;
                #address-cells = <0x1>;
                #size-cells = <0x0>;

                clk_cpu_0: clk_cpu@0 {
                        phandle = <0x54>;
                        compatible = "fixed-clock";
                        reg = <0x0>;
                        clock-frequency = <0x5f5e100>;
                        clock-output-names = "clk_cpu";
                        #clock-cells = <0x0>;
                };
        };

        amba_pl: amba_pl {
                phandle = <0x35>;
                ranges;
                compatible = "simple-bus";
                #address-cells = <0x1>;
                #size-cells = <0x1>;
                firmware-name = "AES128_System_wrapper.bit.bin";

                clocking0: clocking0 {
                        phandle = <0x55>;
                        compatible = "xlnx,fclk";
                        assigned-clocks = <&clkc 0xf>;
                        assigned-clock-rates = <0x5f5e100>;
                        #clock-cells = <0x0>;
                        clock-output-names = "fabric_clk";
                        clocks = <&clkc 0xf>;
                };

                misc_clk_0: misc_clk_0 {
                        phandle = <0x36>;
                        compatible = "fixed-clock";
                        clock-frequency = <0x5f5e100>;
                        #clock-cells = <0x0>;
                };

                microblaze_riscv_0_axi_intc: interrupt-controller@41200000 {
                        phandle = <0x6>;
                        #interrupt-cells = <0x2>;
                        xlnx,sense-of-irq-edge-type = "Rising";
                        xlnx,edk-special = "INTR_CTRL";
                        xlnx,kind-of-intr = <0x3>;
                        xlnx,kind-of-edge = <0xffffffff>;
                        xlnx,irq-is-level = <0x1>;
                        xlnx,has-ivr = <0x1>;
                        compatible = "xlnx,axi-intc-4.1", "xlnx,xps-intc-1.00.a";
                        xlnx,disable-synchronizers = <0x1>;
                        xlnx,kind-of-lvl = <0xffffffff>;
                        xlnx,ivar-reset-value = <0x10>;
                        xlnx,irq-active = <0x1>;
                        xlnx,en-cascade-mode = <0x0>;
                        xlnx,ip-name = "axi_intc";
                        xlnx,has-ilr = <0x0>;
                        reg = <0x41200000 0x10000>;
                        xlnx,addr-width = <0x20>;
                        clocks = <&misc_clk_0>,
                         <&misc_clk_0>;
                        xlnx,s-axi-aclk-freq-mhz = <0x64>;
                        xlnx,num-sw-intr = <0x0>;
                        xlnx,irq-connection = <0x0>;
                        xlnx,num-intr-inputs = <0x2>;
                        xlnx,has-sie = <0x1>;
                        xlnx,enable-async = <0x0>;
                        xlnx,has-cie = <0x1>;
                        xlnx,num-sync-ff = <0x2>;
                        xlnx,edk-iptype = "PERIPHERAL";
                        xlnx,mb-clk-not-connected = <0x1>;
                        xlnx,has-ipr = <0x1>;
                        xlnx,sense-of-irq-level-type = "Active_High";
                        xlnx,cascade-master = <0x0>;
                        xlnx,processor-clk-freq-mhz = <0x64>;
                        status = "okay";
                        xlnx,is-fast = <0x1>;
                        clock-names = "processor_clk", "s_axi_aclk";
                        xlnx,has-fast = <0x1>;
                        xlnx,ivar-rst-val = <0x10>;
                        interrupt-controller;
                        xlnx,async-intr = <0xffffffff>;
                        xlnx,name = "microblaze_riscv_0_axi_intc";
                };

                axi_uartlite_0: serial@40600000 {
                        phandle = <0x5>;
                        compatible = "xlnx,axi-uartlite-2.0", "xlnx,xps-uartlite-1.00.a";
                        xlnx,uartlite-board-interface = "Custom";
                        xlnx,s-axi-aclk-freq-hz-d = <0x64>;
                        xlnx,ip-name = "axi_uartlite";
                        reg = <0x40600000 0x10000>;
                        xlnx,baudrate = <0x2580>;
                        clocks = <&misc_clk_0>;
                        current-speed = <0x2580>;
                        xlnx,use-parity = <0x0>;
                        xlnx,edk-iptype = "PERIPHERAL";
                        xlnx,odd-parity = <0x0>;
                        status = "okay";
                        clock-names = "s_axi_aclk";
                        xlnx,name = "axi_uartlite_0";
                        xlnx,data-bits = <0x8>;
                        xlnx,parity = "No_Parity";
                };

                mdm_1: mdm_riscv@44a00000 {
                        phandle = <0x7>;
                        xlnx,trace-async-reset = <0x0>;
                        compatible = "xlnx,mdm-riscv-1.0";
                        xlnx,data-size = <0x20>;
                        xlnx,addr-size = <0x20>;
                        xlnx,xmtc = <0x0>;
                        xlnx,avoid-primitives = <0x0>;
                        xlnx,bscanid = <0x0>;
                        xlnx,trace-output = <0x0>;
                        xlnx,debug-interface = <0x0>;
                        xlnx,use-uart = <0x1>;
                        xlnx,mb-dbg-ports = <0x1>;
                        xlnx,jtag-chain = <0x2>;
                        xlnx,ext-trig-reset-value = <0xf1234>;
                        xlnx,trig-in-ports = <0x1>;
                        xlnx,ip-name = "mdm_riscv";
                        xlnx,brk = <0x0>;
                        xlnx,dbg-reg-access = <0x0>;
                        xlnx,use-bscan-switch = <0x0>;
                        reg = <0x44a00000 0x10000>;
                        clocks = <&misc_clk_0>;
                        xlnx,use-bscan = <0x0>;
                        xlnx,trace-id = <0x6e>;
                        xlnx,lmb-protocol = <0x0>;
                        xlnx,dtm-idcode = <0x93>;
                        xlnx,trace-data-width = <0x20>;
                        xlnx,edk-iptype = "PERIPHERAL";
                        xlnx,use-jtag-bscan = <0x1>;
                        xlnx,interconnect = <0x2>;
                        xlnx,use-cross-trigger = <0x0>;
                        xlnx,trace-protocol = <0x1>;
                        status = "okay";
                        clock-names = "S_AXI_ACLK";
                        xlnx,use-config-reset = <0x0>;
                        xlnx,trig-out-ports = <0x1>;
                        xlnx,device = "xc7z010";
                        xlnx,dbg-mem-access = <0x0>;
                        xlnx,trace-clk-out-phase = <0x5a>;
                        xlnx,name = "mdm_1";
                };

                microblaze_riscv_0_local_memory_dlmb_bram_if_cntlr: lmb_bram_if_cntlr@0 {
                        phandle = <0x34>;
                        xlnx,edk-special = "BRAM_CTRL";
                        xlnx,write-access = <0x2>;
                        compatible = "xlnx,lmb-bram-if-cntlr-4.0", "xlnx,axi-bram-ctrl";
                        xlnx,ecc-onoff-register = <0x0>;
                        xlnx,ecc-onoff-reset-value = <0x1>;
                        xlnx,s-axi-ctrl-protocol = "AXI4LITE";
                        xlnx,mask = <0x200000>;
                        xlnx,mask1 = <0x800000>;
                        xlnx,mask2 = <0x800000>;
                        xlnx,fault-inject = <0x0>;
                        xlnx,mask3 = <0x800000>;
                        xlnx,ip-name = "lmb_bram_if_cntlr";
                        xlnx,arbitration = <0x0>;
                        xlnx,num-lmb = <0x1>;
                        xlnx,mask4 = <0x800000>;
                        reg = <0x0 0x8000>;
                        xlnx,s-axi-ctrl-addr-width = <0x20>;
                        xlnx,mask5 = <0x800000>;
                        xlnx,ecc-status-registers = <0x0>;
                        xlnx,prot-cfg = <0xff>;
                        xlnx,mask6 = <0x800000>;
                        xlnx,lmb-protocol = <0x0>;
                        xlnx,ce-counter-width = <0x0>;
                        xlnx,prot-cfg1 = <0xff>;
                        xlnx,mask7 = <0x800000>;
                        xlnx,ecc = <0x0>;
                        xlnx,edk-iptype = "PERIPHERAL";
                        xlnx,prot-cfg2 = <0xff>;
                        xlnx,lmb-dwidth = <0x20>;
                        xlnx,interconnect = <0x0>;
                        xlnx,ce-failing-registers = <0x0>;
                        xlnx,prot-cfg3 = <0xff>;
                        xlnx,ue-failing-registers = <0x0>;
                        xlnx,prot-cfg4 = <0xff>;
                        xlnx,lmb-has-prot = <0x0>;
                        status = "okay";
                        xlnx,data-width = <0x20>;
                        xlnx,prot-cfg5 = <0xff>;
                        xlnx,s-axi-ctrl-data-width = <0x20>;
                        xlnx,prot-cfg6 = <0xff>;
                        xlnx,bram-awidth = <0x20>;
                        xlnx,prot-cfg7 = <0xff>;
                        xlnx,lmb-awidth = <0x20>;
                        xlnx,name = "microblaze_riscv_0_local_memory_dlmb_bram_if_cntlr";
                };

                microblaze_riscv_0_local_memory_ilmb_bram_if_cntlr: microblaze_riscv_0_local_memory_ilmb_bram_if_cntlr@0 {
                        phandle = <0x56>;
                        xlnx,edk-special = "BRAM_CTRL";
                        xlnx,write-access = <0x2>;
                        compatible = "xlnx,lmb-bram-if-cntlr-4.0", "xlnx,axi-bram-ctrl";
                        xlnx,ecc-onoff-register = <0x0>;
                        xlnx,ecc-onoff-reset-value = <0x1>;
                        xlnx,s-axi-ctrl-protocol = "AXI4LITE";
                        xlnx,mask = <0x0>;
                        xlnx,mask1 = <0x800000>;
                        xlnx,mask2 = <0x800000>;
                        xlnx,fault-inject = <0x0>;
                        xlnx,mask3 = <0x800000>;
                        xlnx,ip-name = "lmb_bram_if_cntlr";
                        xlnx,arbitration = <0x0>;
                        xlnx,num-lmb = <0x1>;
                        xlnx,mask4 = <0x800000>;
                        reg = <0x0 0x8000>;
                        xlnx,s-axi-ctrl-addr-width = <0x20>;
                        xlnx,mask5 = <0x800000>;
                        xlnx,ecc-status-registers = <0x0>;
                        xlnx,prot-cfg = <0xff>;
                        xlnx,mask6 = <0x800000>;
                        xlnx,lmb-protocol = <0x0>;
                        xlnx,ce-counter-width = <0x0>;
                        xlnx,prot-cfg1 = <0xff>;
                        xlnx,mask7 = <0x800000>;
                        xlnx,ecc = <0x0>;
                        xlnx,edk-iptype = "PERIPHERAL";
                        xlnx,prot-cfg2 = <0xff>;
                        xlnx,lmb-dwidth = <0x20>;
                        xlnx,interconnect = <0x0>;
                        xlnx,ce-failing-registers = <0x0>;
                        xlnx,prot-cfg3 = <0xff>;
                        xlnx,ue-failing-registers = <0x0>;
                        xlnx,prot-cfg4 = <0xff>;
                        xlnx,lmb-has-prot = <0x0>;
                        status = "okay";
                        xlnx,prot-cfg5 = <0xff>;
                        xlnx,s-axi-ctrl-data-width = <0x20>;
                        xlnx,prot-cfg6 = <0xff>;
                        xlnx,bram-awidth = <0x20>;
                        xlnx,prot-cfg7 = <0xff>;
                        xlnx,lmb-awidth = <0x20>;
                        xlnx,name = "microblaze_riscv_0_local_memory_ilmb_bram_if_cntlr";
                };
        };

        microblaze_riscv_0_local_memory_dlmb_bram_if_cntlr_memory: memory@0 {
                phandle = <0x33>;
                compatible = "xlnx,lmb-bram-if-cntlr-4.0";
                xlnx,ip-name = "lmb_bram_if_cntlr";
                device_type = "memory";
                memory_type = "memory";
                reg = <0x0 0x0 0x0 0x8000>;
        };

        ps7_qspi_linear_0_memory: memory@fc000000 {
                phandle = <0x1b>;
                compatible = "xlnx,ps7-qspi-linear-1.00.a-memory";
                xlnx,ip-name = "ps7_qspi_linear";
                device_type = "memory";
                memory_type = "linear_flash";
                reg = <0xfc000000 0x1000000>;
        };

        ps7_ddr_0_memory: memory@00100000 {
                phandle = <0x2>;
                compatible = "xlnx,ps7-ddr-1.00.a";
                xlnx,ip-name = "ps7_ddr";
                device_type = "memory";
                memory_type = "memory";
                reg = <0x100000 0x1ff00000>;
        };

        ps7_ram_0_memory: memory@00 {
                phandle = <0x3>;
                compatible = "xlnx,ps7-ram-1.00.a";
                xlnx,ip-name = "ps7_ram";
                device_type = "memory";
                memory_type = "memory";
                reg = <0x0 0x30000>;
        };

        ps7_ram_1_memory: memory@ffff0000 {
                phandle = <0x4>;
                compatible = "xlnx,ps7-ram-1.00.a";
                xlnx,ip-name = "ps7_ram";
                device_type = "memory";
                memory_type = "memory";
                reg = <0xffff0000 0xfe00>;
        };

        chosen {
                stdout-path = "serial0:9600n8";
        };

        aliases {
                serial0 = "/axi/serial@e0001000";
                spi0 = "/axi/spi@e000d000";
                serial1 = "/amba_pl/serial@40600000";
                serial2 = "/axi/coresight@f8800000";
                ethernet0 = "/axi/ethernet@e000b000";
        };

        __symbols__ {
                cpus_a9 = "/cpus-a9@0";
                ps7_cortexa9_0 = "/cpus-a9@0/cpu@0";
                ps7_cortexa9_1 = "/cpus-a9@0/cpu@1";
                fpga_full = "/fpga-region";
                regulator_vccpint = "/fixedregulator";
                replicator_out_port0 = "/replicator/out-ports/port@0/endpoint";
                replicator_out_port1 = "/replicator/out-ports/port@1/endpoint";
                replicator_in_port0 = "/replicator/in-ports/port/endpoint";
                amba = "/axi";
                adc = "/axi/adc@f8007100";
                can0 = "/axi/can@e0008000";
                can1 = "/axi/can@e0009000";
                gpio0 = "/axi/gpio@e000a000";
                i2c0 = "/axi/i2c@e0004000";
                i2c1 = "/axi/i2c@e0005000";
                intc = "/axi/interrupt-controller@f8f01000";
                L2 = "/axi/cache-controller@f8f02000";
                mc = "/axi/memory-controller@f8006000";
                ocm = "/axi/sram@fffc0000";
                uart0 = "/axi/serial@e0000000";
                uart1 = "/axi/serial@e0001000";
                spi0 = "/axi/spi@e0006000";
                spi1 = "/axi/spi@e0007000";
                qspi = "/axi/spi@e000d000";
                gem0 = "/axi/ethernet@e000b000";
                gem1 = "/axi/ethernet@e000c000";
                smcc = "/axi/memory-controller@e000e000";
                nfc0 = "/axi/memory-controller@e000e000/nand-controller@0,0";
                nor0 = "/axi/memory-controller@e000e000/flash@1,0";
                sdhci0 = "/axi/mmc@e0100000";
                sdhci1 = "/axi/mmc@e0101000";
                slcr = "/axi/slcr@f8000000";
                clkc = "/axi/slcr@f8000000/clkc@100";
                rstc = "/axi/slcr@f8000000/rstc@200";
                pinctrl0 = "/axi/slcr@f8000000/pinctrl@700";
                dmac_s = "/axi/dma-controller@f8003000";
                devcfg = "/axi/devcfg@f8007000";
                efuse = "/axi/efuse@f800d000";
                global_timer = "/axi/timer@f8f00200";
                ttc0 = "/axi/timer@f8001000";
                ttc1 = "/axi/timer@f8002000";
                scutimer = "/axi/timer@f8f00600";
                scuwdt = "/axi/scuwatchdog@f8f00620";
                usb0 = "/axi/usb@e0002000";
                usb1 = "/axi/usb@e0003000";
                watchdog0 = "/axi/watchdog@f8005000";
                coresight = "/axi/coresight@f8800000";
                etb_in_port = "/axi/etb@f8801000/in-ports/port/endpoint";
                tpiu_in_port = "/axi/tpiu@f8803000/in-ports/port/endpoint";
                funnel_out_port = "/axi/funnel@f8804000/out-ports/port/endpoint";
                funnel0_in_port0 = "/axi/funnel@f8804000/in-ports/port@0/endpoint";
                funnel0_in_port1 = "/axi/funnel@f8804000/in-ports/port@1/endpoint";
                ptm0_out_port = "/axi/ptm@f889c000/out-ports/port/endpoint";
                ptm1_out_port = "/axi/ptm@f889d000/out-ports/port/endpoint";
                ps7_pmu_0 = "/axi/ps7_pmu@f8891000";
                ps7_ddr_0 = "/axi/ps7_ddr@100000";
                ps7_ocmc_0 = "/axi/ps7_ocmc@f800c000";
                ps7_gpv_0 = "/axi/ps7_gpv@f8900000";
                ps7_scuc_0 = "/axi/ps7_scuc@f8f00000";
                ps7_iop_bus_config_0 = "/axi/ps7_iop_bus_config@e0200000";
                ps7_ram_0 = "/axi/ps7_ram@0";
                ps7_ram_1 = "/axi/ps7_ram@ffff0000";
                ps7_dma_ns = "/axi/ps7_dma@f8004000";
                ps7_afi_0 = "/axi/ps7_afi@f8008000";
                ps7_afi_1 = "/axi/ps7_afi@f8009000";
                ps7_afi_2 = "/axi/ps7_afi@f800a000";
                ps7_afi_3 = "/axi/ps7_afi@f800b000";
                ps7_m_axi_gp0 = "/axi/ps7_m_axi_gp@40000000";
                ps7_qspi_linear_0 = "/axi/ps7_qspi_linear@fc000000";
                cpus_microblaze_riscv_0 = "/cpus_microblaze_riscv@0";
                microblaze_riscv_0 = "/cpus_microblaze_riscv@0/cpu@0";
                clock = "/clocks";
                clk_cpu_0 = "/clocks/clk_cpu@0";
                amba_pl = "/amba_pl";
                clocking0 = "/amba_pl/clocking0";
                misc_clk_0 = "/amba_pl/misc_clk_0";
                microblaze_riscv_0_axi_intc = "/amba_pl/interrupt-controller@41200000";
                axi_uartlite_0 = "/amba_pl/serial@40600000";
                mdm_1 = "/amba_pl/mdm_riscv@44a00000";
                microblaze_riscv_0_local_memory_dlmb_bram_if_cntlr = "/amba_pl/lmb_bram_if_cntlr@0";
                microblaze_riscv_0_local_memory_ilmb_bram_if_cntlr = "/amba_pl/microblaze_riscv_0_local_memory_ilmb_bram_if_cntlr@0";
                microblaze_riscv_0_local_memory_dlmb_bram_if_cntlr_memory = "/memory@0";
                ps7_qspi_linear_0_memory = "/memory@fc000000";
                ps7_ddr_0_memory = "/memory@00100000";
                ps7_ram_0_memory = "/memory@00";
                ps7_ram_1_memory = "/memory@ffff0000";
        };
};
